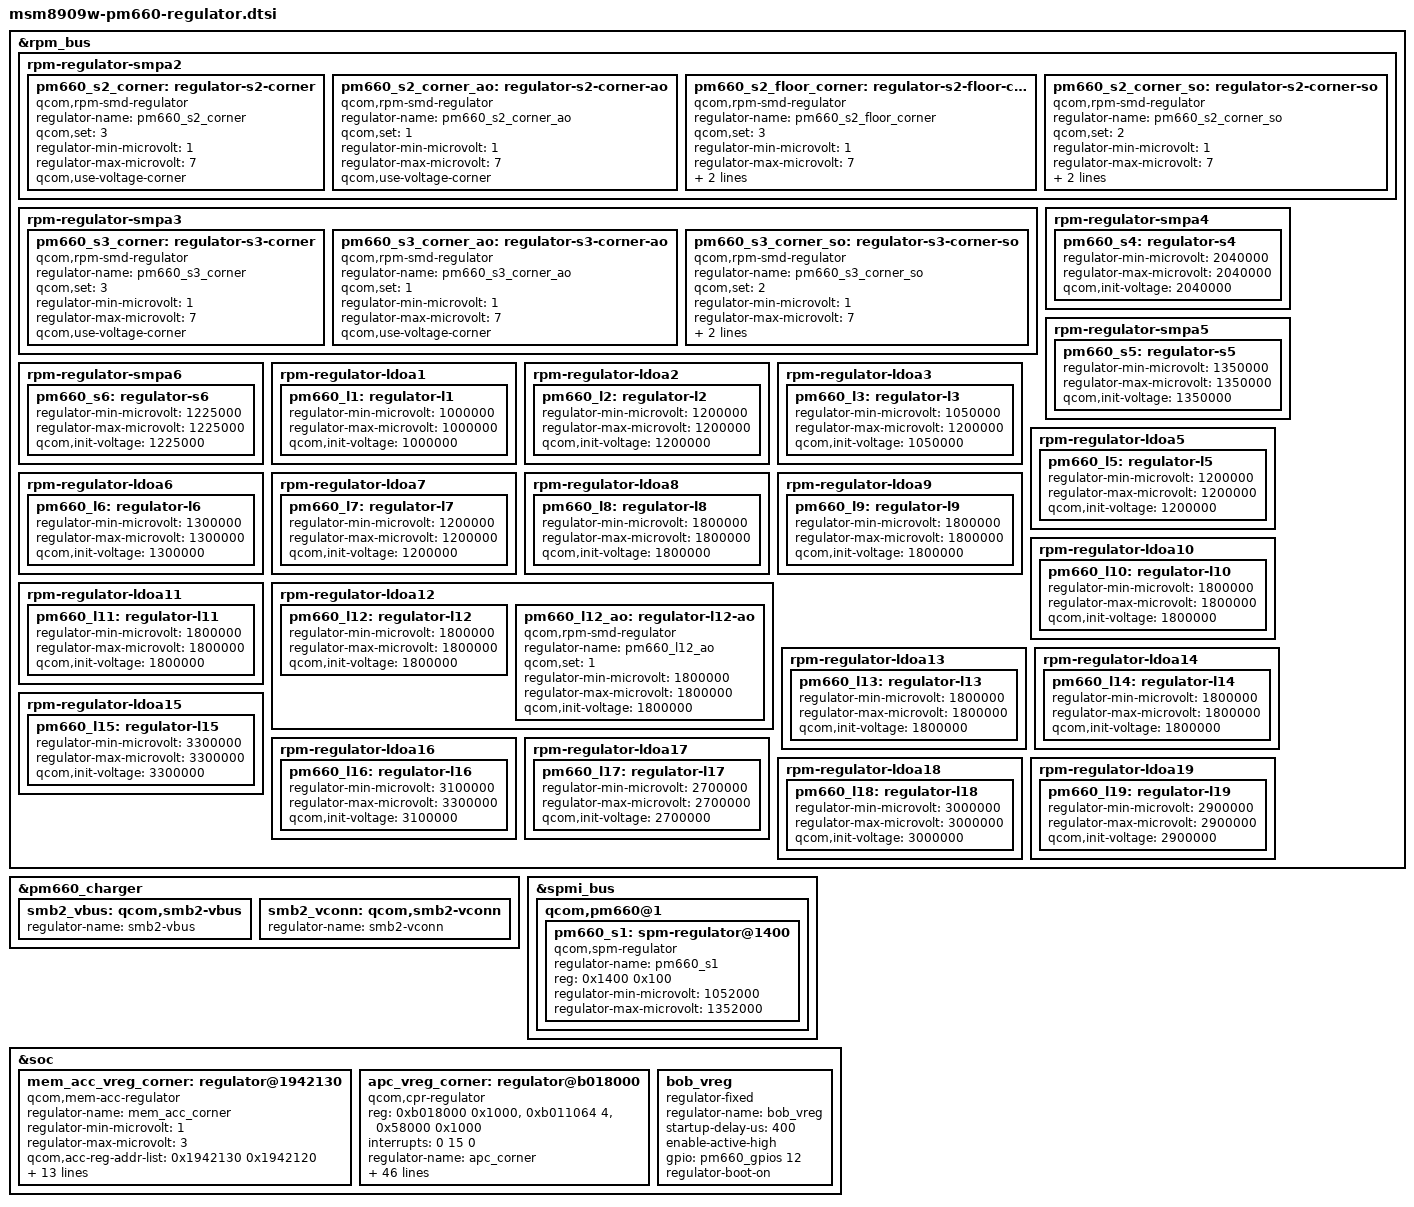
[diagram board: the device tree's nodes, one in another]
/* Copyright (c) 2017-2018, The Linux Foundation. All rights reserved.
 *
 * This program is free software; you can redistribute it and/or modify
 * it under the terms of the GNU General Public License version 2 and
 * only version 2 as published by the Free Software Foundation.
 *
 * This program is distributed in the hope that it will be useful,
 * but WITHOUT ANY WARRANTY; without even the implied warranty of
 * MERCHANTABILITY or FITNESS FOR A PARTICULAR PURPOSE.  See the
 * GNU General Public License for more details.
 */

&rpm_bus {
	/* CX supply */
	rpm-regulator-smpa2 {
		status = "okay";
		pm660_s2_corner: regulator-s2-corner {
			compatible = "qcom,rpm-smd-regulator";
			regulator-name = "pm660_s2_corner";
			qcom,set = <3>;
			regulator-min-microvolt = <1>;
			regulator-max-microvolt = <7>;
			qcom,use-voltage-corner;
			status = "okay";
		};

		pm660_s2_corner_ao: regulator-s2-corner-ao {
			compatible = "qcom,rpm-smd-regulator";
			regulator-name = "pm660_s2_corner_ao";
			qcom,set = <1>;
			regulator-min-microvolt = <1>;
			regulator-max-microvolt = <7>;
			qcom,use-voltage-corner;
		};

		pm660_s2_floor_corner: regulator-s2-floor-corner {
			compatible = "qcom,rpm-smd-regulator";
			regulator-name = "pm660_s2_floor_corner";
			qcom,set = <3>;
			regulator-min-microvolt = <1>;
			regulator-max-microvolt = <7>;
			qcom,use-voltage-floor-corner;
			qcom,always-send-voltage;
		};

		pm660_s2_corner_so: regulator-s2-corner-so {
			compatible = "qcom,rpm-smd-regulator";
			regulator-name = "pm660_s2_corner_so";
			qcom,set = <2>;
			regulator-min-microvolt = <1>;
			regulator-max-microvolt = <7>;
			qcom,init-voltage = <1>;
			qcom,use-voltage-corner;
		};
	};

	/* MX supply */
	rpm-regulator-smpa3 {
		status = "okay";
		pm660_s3_corner: regulator-s3-corner {
			compatible = "qcom,rpm-smd-regulator";
			regulator-name = "pm660_s3_corner";
			qcom,set = <3>;
			regulator-min-microvolt = <1>;
			regulator-max-microvolt = <7>;
			qcom,use-voltage-corner;
			status = "okay";
		};

		pm660_s3_corner_ao: regulator-s3-corner-ao {
			compatible = "qcom,rpm-smd-regulator";
			regulator-name = "pm660_s3_corner_ao";
			qcom,set = <1>;
			regulator-min-microvolt = <1>;
			regulator-max-microvolt = <7>;
			qcom,use-voltage-corner;
		};

		pm660_s3_corner_so: regulator-s3-corner-so {
			compatible = "qcom,rpm-smd-regulator";
			regulator-name = "pm660_s3_corner_so";
			qcom,set = <2>;
			regulator-min-microvolt = <1>;
			regulator-max-microvolt = <7>;
			qcom,init-voltage = <1>;
			qcom,use-voltage-corner;
		};
	};

	rpm-regulator-smpa4 {
		status = "okay";
		pm660_s4: regulator-s4 {
			regulator-min-microvolt = <2040000>;
			regulator-max-microvolt = <2040000>;
			qcom,init-voltage = <2040000>;
			status = "okay";
		};
	};

	rpm-regulator-smpa5 {
		status = "okay";
		pm660_s5: regulator-s5 {
			regulator-min-microvolt = <1350000>;
			regulator-max-microvolt = <1350000>;
			qcom,init-voltage = <1350000>;
			status = "okay";
		};
	};

	rpm-regulator-smpa6 {
		status = "okay";
		pm660_s6: regulator-s6 {
			regulator-min-microvolt = <1225000>;
			regulator-max-microvolt = <1225000>;
			qcom,init-voltage = <1225000>;
			status = "okay";
		};
	};

	rpm-regulator-ldoa1 {
		status = "okay";
		pm660_l1: regulator-l1 {
			regulator-min-microvolt = <1000000>;
			regulator-max-microvolt = <1000000>;
			qcom,init-voltage = <1000000>;
			status = "okay";
		};
	};

	rpm-regulator-ldoa2 {
		status = "okay";
		pm660_l2: regulator-l2 {
			regulator-min-microvolt = <1200000>;
			regulator-max-microvolt = <1200000>;
			qcom,init-voltage = <1200000>;
			status = "okay";
		};
	};

	rpm-regulator-ldoa3 {
		status = "okay";
		pm660_l3: regulator-l3 {
			regulator-min-microvolt = <1050000>;
			regulator-max-microvolt = <1200000>;
			qcom,init-voltage = <1050000>;
			status = "okay";
		};
	};

	rpm-regulator-ldoa5 {
		status = "okay";
		pm660_l5: regulator-l5 {
			regulator-min-microvolt = <1200000>;
			regulator-max-microvolt = <1200000>;
			qcom,init-voltage = <1200000>;
			status = "okay";
		};
	};

	rpm-regulator-ldoa6 {
		status = "okay";
		pm660_l6: regulator-l6 {
			regulator-min-microvolt = <1300000>;
			regulator-max-microvolt = <1300000>;
			qcom,init-voltage = <1300000>;
			status = "okay";
		};
	};

	rpm-regulator-ldoa7 {
		status = "okay";
		pm660_l7: regulator-l7 {
			regulator-min-microvolt = <1200000>;
			regulator-max-microvolt = <1200000>;
			qcom,init-voltage = <1200000>;
			status = "okay";
		};
	};

	rpm-regulator-ldoa8 {
		status = "okay";
		pm660_l8: regulator-l8 {
			regulator-min-microvolt = <1800000>;
			regulator-max-microvolt = <1800000>;
			qcom,init-voltage = <1800000>;
			status = "okay";
		};
	};

	rpm-regulator-ldoa9 {
		status = "okay";
		pm660_l9: regulator-l9 {
			regulator-min-microvolt = <1800000>;
			regulator-max-microvolt = <1800000>;
			qcom,init-voltage = <1800000>;
			status = "okay";
		};
	};

	rpm-regulator-ldoa10 {
		status = "okay";
		pm660_l10: regulator-l10 {
			regulator-min-microvolt = <1800000>;
			regulator-max-microvolt = <1800000>;
			qcom,init-voltage = <1800000>;
			status = "okay";
		};
	};

	rpm-regulator-ldoa11 {
		status = "okay";
		pm660_l11: regulator-l11 {
			regulator-min-microvolt = <1800000>;
			regulator-max-microvolt = <1800000>;
			qcom,init-voltage = <1800000>;
			status = "okay";
		};
	};

	rpm-regulator-ldoa12 {
		status = "okay";
		pm660_l12: regulator-l12 {
			regulator-min-microvolt = <1800000>;
			regulator-max-microvolt = <1800000>;
			qcom,init-voltage = <1800000>;
			status = "okay";
		};

		pm660_l12_ao: regulator-l12-ao {
			compatible = "qcom,rpm-smd-regulator";
			regulator-name = "pm660_l12_ao";
			qcom,set = <1>;
			regulator-min-microvolt = <1800000>;
			regulator-max-microvolt = <1800000>;
			qcom,init-voltage = <1800000>;
		};
	};

	rpm-regulator-ldoa13 {
		status = "okay";
		pm660_l13: regulator-l13 {
			regulator-min-microvolt = <1800000>;
			regulator-max-microvolt = <1800000>;
			qcom,init-voltage = <1800000>;
			status = "okay";
		};
	};

	rpm-regulator-ldoa14 {
		status = "okay";
		pm660_l14: regulator-l14 {
			regulator-min-microvolt = <1800000>;
			regulator-max-microvolt = <1800000>;
			qcom,init-voltage = <1800000>;
			status = "okay";
		};
	};

	rpm-regulator-ldoa15 {
		status = "okay";
		pm660_l15: regulator-l15 {
			regulator-min-microvolt = <3300000>;
			regulator-max-microvolt = <3300000>;
			qcom,init-voltage = <3300000>;
			status = "okay";
		};
	};

	rpm-regulator-ldoa16 {
		status = "okay";
		pm660_l16: regulator-l16 {
			regulator-min-microvolt = <3100000>;
			regulator-max-microvolt = <3300000>;
			qcom,init-voltage = <3100000>;
			status = "okay";
		};
	};

	rpm-regulator-ldoa17 {
		status = "okay";
		pm660_l17: regulator-l17 {
			regulator-min-microvolt = <2700000>;
			regulator-max-microvolt = <2700000>;
			qcom,init-voltage = <2700000>;
			status = "okay";
		};
	};

	rpm-regulator-ldoa18 {
		status = "okay";
		pm660_l18: regulator-l18 {
			regulator-min-microvolt = <3000000>;
			regulator-max-microvolt = <3000000>;
			qcom,init-voltage = <3000000>;
			status = "okay";
		};
	};

	rpm-regulator-ldoa19 {
		status = "okay";
		pm660_l19: regulator-l19 {
			regulator-min-microvolt = <2900000>;
			regulator-max-microvolt = <2900000>;
			qcom,init-voltage = <2900000>;
			status = "okay";
		};
	};
};

&pm660_charger {
	smb2_vbus: qcom,smb2-vbus {
		regulator-name = "smb2-vbus";
	};

	smb2_vconn: qcom,smb2-vconn {
		regulator-name = "smb2-vconn";
	};
};

/* SPM controlled regulators */
&spmi_bus {
	qcom,pm660@1 {
		pm660_s1: spm-regulator@1400 {
			compatible = "qcom,spm-regulator";
			regulator-name = "pm660_s1";
			reg = <0x1400 0x100>;
			regulator-min-microvolt = <1052000>;
			regulator-max-microvolt = <1352000>;
		};
	};
};

/* CPR controlled regulator */
&soc {
	/delete-node/ regulator@1942130;
	mem_acc_vreg_corner: regulator@1942130 {
		compatible = "qcom,mem-acc-regulator";
		regulator-name = "mem_acc_corner";
		regulator-min-microvolt = <1>;
		regulator-max-microvolt = <3>;

		qcom,acc-reg-addr-list =
				<0x1942130 0x1942120>;

		qcom,acc-init-reg-config = <1 0x1>, <2 0x0>;
		qcom,num-acc-corners = <3>;
		qcom,boot-acc-corner = <2>;

		qcom,corner1-reg-config =
			/* SVS => SVS */
			<(-1) (-1)>,     <(-1) (-1)>,   <(-1) (-1)>,
			/* SVS => NOM */
			<  1 0x0 >, <  2  0x09240000>,	< 1 0x1 >,
			/* SVS => TURBO */
			<  1 0x1 >, <  2  0x0>,	< (-1) (-1) >;

		qcom,corner2-reg-config =
			/* NOM => SVS */
			<  1 0x0 >, <  2  0x09240000>,	< 2 0x0 >,
			/* NOM => NOM */
			<(-1) (-1)>,     <(-1) (-1)>,  <(-1) (-1)>,
			/* NOM => TURBO */
			<  1 0x1 >, <  2  0x08200000>,	< 2  0x0 >;

		qcom,corner3-reg-config =
			/* TURBO => SVS */
			<  1 0x0 >, <  2  0x0>,	< (-1) (-1) >,
			/* TURBO => NOM */
			<  1 0x1 >, <  2  0x08200000>,	< 2  0x09240000 >,
			/* TURBO => TURBO */
			<(-1) (-1)>,     <(-1) (-1)>,   <(-1) (-1)>;
	};

	apc_vreg_corner: regulator@b018000 {
		compatible = "qcom,cpr-regulator";
		reg = <0xb018000 0x1000>, <0xb011064 4>, <0x58000 0x1000>;
		reg-names = "rbcpr", "rbcpr_clk", "efuse_addr";
		interrupts = <0 15 0>;
		regulator-name = "apc_corner";
		qcom,cpr-fuse-corners = <3>;
		regulator-min-microvolt = <1>;
		regulator-max-microvolt = <9>;

		qcom,cpr-voltage-ceiling = <1052000 1228000 1352000>;
		qcom,cpr-voltage-floor = <1052000 1052000 1156000>;
		vdd-apc-supply = <&pm660_s1>;

		qcom,vdd-mx-corner-map = <4 5 7>;
		qcom,vdd-mx-vmin-method = <4>;
		vdd-mx-supply = <&pm660_s3_corner_ao>;
		qcom,vdd-mx-vmax = <7>;

		mem-acc-supply = <&mem_acc_vreg_corner>;

		qcom,cpr-ref-clk = <19200>;
		qcom,cpr-timer-delay = <5000>;
		qcom,cpr-timer-cons-up = <0>;
		qcom,cpr-timer-cons-down = <2>;
		qcom,cpr-irq-line = <0>;
		qcom,cpr-step-quotient = <10>;
		qcom,cpr-up-threshold = <0>;
		qcom,cpr-down-threshold = <2>;
		qcom,cpr-idle-clocks = <15>;
		qcom,cpr-gcnt-time = <1>;
		qcom,vdd-apc-step-up-limit = <1>;
		qcom,vdd-apc-step-down-limit = <1>;
		qcom,cpr-apc-volt-step = <4000>;

		qcom,cpr-fuse-row = <26 0>;
		qcom,cpr-fuse-target-quot = <42 24 6>;
		qcom,cpr-fuse-ro-sel = <61 61 54>;
		qcom,cpr-fuse-bp-cpr-disable = <58>;
		qcom,cpr-fuse-init-voltage =
					<26 36 6 0>,
					<26 18 6 0>,
					<26 0 6 0>;
		qcom,cpr-fuse-revision = <26 59 2 0>;
		qcom,cpr-init-voltage-ref = <1052000 1228000 1352000>;
		qcom,cpr-init-voltage-step = <10000>;
		qcom,cpr-corner-map = <1 1 2 2 3 3 3 3 3>;
		qcom,cpr-init-voltage-as-ceiling;
		qcom,cpr-corner-frequency-map =
					<1 200000000>,
					<2 400000000>,
					<3 533330000>,
					<4 800000000>,
					<5 998400000>,
					<6 1094400000>,
					<7 1190400000>,
					<8 1248000000>,
					<9 1267200000>;
		qcom,speed-bin-fuse-sel = <1 34 3 0>;
		qcom,cpr-speed-bin-max-corners =
					<0 (-1) 2 4 9>,
					<2 (-1) 2 4 6>;
		qcom,cpr-quot-adjust-scaling-factor-max = <1400>;
	};

	bob_vreg: bob_vreg {
		compatible = "regulator-fixed";
		regulator-name = "bob_vreg";
		startup-delay-us = <400>;
		enable-active-high;
		gpio = <&pm660_gpios 12 0>;
		status = "okay";
		regulator-boot-on;
	};
};
